# LPC12D27 register map
File version: 3
Registers are 32-bit, read-write, reset 0x0 unless marked. A register's access mark holds for its fields unless they carry their own. Offsets are from the block's base; [hi:lo] are bit positions; {n}, {i} and the like mark numbered series.

## ADC — Product name title=UM10441 Chapter title=LPC122x ADC Modification date=2/9/2011 Major revision=0 Minor revision=17
Base 0x40020000
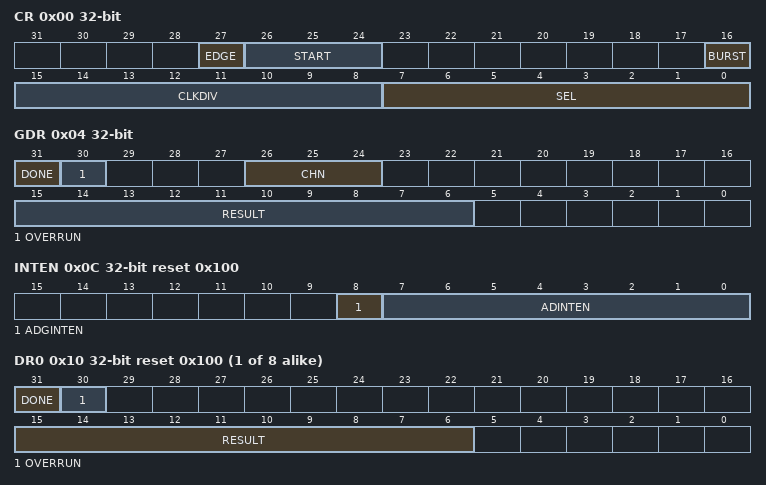
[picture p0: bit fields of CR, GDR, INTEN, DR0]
0x00 CR — A/D Control Register. The CR register must be written to select the operating mode before A/D conversion can occur.
  [27] EDGE — Edge control. This bit is significant only when the START field contains 010-111.
    1=FALLING (Start conversion on a falling edge on the selected CAP/MAT signal.); 0=RISING (Start conversion on a rising edge on the selected CAP/MAT signal.)
  [26:24] START — Conversion start control. When the BURST bit is 0, these bits control whether and when an A/D conversion is started.
    0=NOSTART (No start (this value should be used when clearing PDN to 0).); 1=START (Start conversion now.); 2=STARTONPIO0_2 (Start conversion when the edge selected by bit 27 occurs on PIO0_2/SSEL/CT16B0_CAP0.); 3=STARTONPIO1_5 (Start conversion when the edge selected by bit 27 occurs on PIO1_5/DIR/CT32B0_CAP0.); 4=STARTONCT32B0_MAT0 (Start conversion when the edge selected by bit 27 occurs on CT32B0_MAT0.); 5=STARTONCT32B0_MAT1 (Start conversion when the edge selected by bit 27 occurs on CT32B0_MAT1.); 6=STARTONCT16B0_MAT0 (Start conversion when the edge selected by bit 27 occurs on CT16B0_MAT0.); 7=STARTONCT16B0_MAT1 (Start conversion when the edge selected by bit 27 occurs on CT16B0_MAT1.)
  [16] BURST — Burst mode control.
    0=SOFTWARE (Conversions are software controlled and require 36 clocks.); 1=BURST (The AD converter does repeated conversions up to 250 kHz, scanning (if necessary) through the pins selected by 1s in the SEL field. The first conversion after the start corresponds to the least-significant 1 in the SEL field, then higher numbered 1 bits (pins) if applicable. Repeated conversions can be terminated by clearing this bit, but the conversion that is in progress when this bit is cleared will be completed. Important: START bits must be 000 when BURST = 1 or conversions will not start.)
  [15:8] CLKDIV — The APB clock (PCLK) is divided by (this value plus one) to produce the clock for the A/D converter, which should be less than or equal to 9 MHz. Typically, software should program the smallest value in this field that yields a clock of 9 MHz or slightly less, but in certain cases (such as a high-impedance analog source) a slower clock may be desirable.
  [7:0] SEL — Selects which of the AD7:0 pins is (are) to be sampled and converted. For ADC, bit 0 selects Pin AD0, and bit 7 selects pin AD7. In software-controlled mode, only one of these bits should be 1. In hardware scan mode, any value containing 1 to 8 ones. All zeroes is equivalent to 0x01.
0x04 GDR — A/D Global Data Register. Contains the result of the most recent A/D conversion.
  [31] DONE — This bit is set to 1 when an A/D conversion completes. It is cleared when this register is read and when the ADCR is written. If the ADCR is written while a conversion is still in progress, this bit is set and a new conversion is started.
  [30] OVERRUN — This bit is 1 in burst mode if the results of one or more conversions was (were) lost and overwritten before the conversion that produced the result in the RESULT bits.
  [26:24] CHN — These bits contain the channel from which the RESULT bits were converted.
  [15:6] RESULT — When DONE is 1, this field contains a binary fraction representing the voltage on the ADn pin selected by the SEL field, divided by the voltage on the VDD(3V3) pin: V/VREF. Zero in the field indicates that the voltage on the ADn pin was less than, equal to, or close to that on VSS, while 0x3FF indicates that the voltage on ADn was close to, equal to, or greater than that on VREF.
0x0C INTEN reset 0x100 — A/D Interrupt Enable Register. This register contains enable bits that allow the DONE flag of each A/D channel to be included or excluded from contributing to the generation of an A/D interrupt.
  [8] ADGINTEN — When 1, enables the global DONE flag in ADDR to generate an interrupt. When 0, only the individual A/D channels enabled by ADINTEN 7:0 will generate interrupts.
  [7:0] ADINTEN — These bits allow control over which A/D channels generate interrupts for conversion completion. When bit 0 is one, completion of a conversion on A/D channel 0 will generate an interrupt, when bit 1 is one, completion of a conversion on A/D channel 1 will generate an interrupt, etc.
{0x10+4i} DR{i} (i=0..7) reset 0x100 — A/D Channel Data Register. This register contains the result of the most recent conversion completed on channel.
  [31] DONE — This bit is set to 1 when an A/D conversion completes. It is cleared when this register is read.
  [30] OVERRUN — This bit is 1 in burst mode if the results of one or more conversions was (were) lost and overwritten before the conversion that produced the result in the RESULT bits.This bit is cleared by reading this register.
  [15:6] RESULT — When DONE is 1, this field contains a binary fraction representing the voltage on the ADn pin selected by the SEL field, divided by the voltage on the VDD(3V3) pin: V/VREF. Zero in the field indicates that the voltage on the ADn pin was less than, equal to, or close to that on VSSA, while 0x3FF indicates that the voltage on ADn was close to, equal to, or greater than that on VREF.
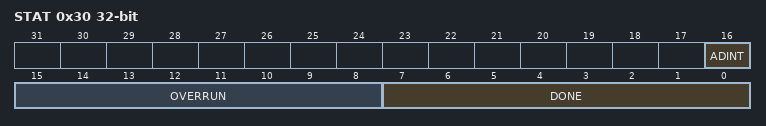
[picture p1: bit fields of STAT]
0x30 STAT ro — A/D Status Register. This register contains DONE and OVERRUN flags for all of the A/D channels, as well as the A/D interrupt flag.
  [16] ADINT — This bit is the A/D interrupt flag. It is one when any of the individual A/D channel Done flags is asserted and enabled to contribute to the A/D interrupt via the ADINTEN register.
  [15:8] OVERRUN — These bits mirror the OVERRRUN status flags that appear in the result register for each A/D channel. Reading ADSTAT allows checking the status of all A/D channels simultaneously.
  [7:0] DONE — These bits mirror the DONE status flags that appear in the result register for each A/D channel.
0x34 TRM — A/D trim register
  [7:4] ADCOFFS — Offset trim bits for ADC operation. Initialized by the boot code. Can be overwritten by the user.
